VERSION ""

NS_ :

BS_:

BU_: SR_Battery XR_Battery SR_ESC

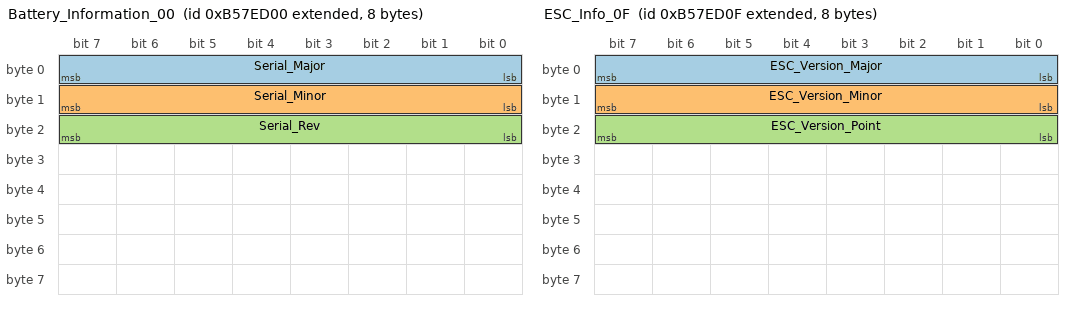
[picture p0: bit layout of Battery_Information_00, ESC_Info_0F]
BO_ 2337795328 Battery_Information_00: 8 SR_Battery
 SG_ Serial_Major : 0|8@1+ (1,0) [0|0] ""  SR_Battery
 SG_ Serial_Minor : 8|8@1+ (1,0) [0|0] ""  SR_Battery
 SG_ Serial_Rev : 16|8@1+ (1,0) [0|0] ""  SR_Battery

BO_ 2337795329 Battery_Information_01: 8 SR_Battery
 SG_ Serial : 0|32@1+ (1,0) [0|0] ""  SR_Battery

BO_ 2337795348 Battery_Information_14: 8 SR_Battery
 SG_ Battery_Charge : 32|8@1+ (1,0) [0|0] "%"  SR_Battery

BO_ 2337795343 ESC_Info_0F: 8 SR_ESC
 SG_ ESC_Version_Major : 0|8@1+ (1,0) [0|0] ""  SR_ESC
 SG_ ESC_Version_Minor : 8|8@1+ (1,0) [0|0] ""  SR_ESC
 SG_ ESC_Version_Point : 16|8@1+ (1,0) [0|0] ""  SR_ESC

CM_ BU_ SR_Battery "Short Range Battery";
CM_ BU_ XR_Battery "Long Range Battery";
CM_ BU_ SR_ESC "ESC to SR Battery";
